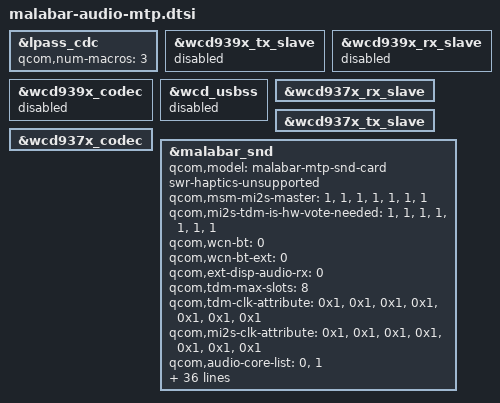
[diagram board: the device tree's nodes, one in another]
//
/* Copyright (c) Qualcomm Technologies, Inc. and/or its subsidiaries.
 * SPDX-License-Identifier: BSD-3-Clause-Clear
 */

#include "lpass-audio-cdc-1.0.dtsi"
#include "malabar-lpi.dtsi"
#include "lpass-audio-bt-swr.dtsi"
#include "lpass-cdc-gpio.dtsi"
#include "malabar-audio-lpass-reg.dtsi"
#include "wcd939x.dtsi"

&lpass_cdc {
	qcom,num-macros = <3>;
};

&wcd939x_tx_slave {
	status = "disabled";
};

&wcd939x_rx_slave {
	status = "disabled";
};

&wcd939x_codec {
	status = "disabled";
};

&wcd_usbss {
	status = "disabled";
};

&wcd937x_rx_slave {
	status = "okay";
};

&wcd937x_tx_slave {
	status = "okay";
};

&wcd937x_codec {
	status = "okay";
};

&malabar_snd {
	qcom,model = "malabar-mtp-snd-card";
	swr-haptics-unsupported;
	qcom,msm-mi2s-master = <1>, <1>, <1>, <1>, <1>, <1>, <1>;
	qcom,mi2s-tdm-is-hw-vote-needed = <1>, <1>, <1>, <1>, <1>, <1>, <1>;
	qcom,wcn-bt = <0>;
	qcom,wcn-bt-ext = <0>;
	qcom,ext-disp-audio-rx = <0>;
	qcom,tdm-max-slots = <8>;
	qcom,tdm-clk-attribute = <0x1>, <0x1>, <0x1>, <0x1>, <0x1>, <0x1>, <0x1>;
	qcom,mi2s-clk-attribute = <0x1>, <0x1>, <0x1>, <0x1>, <0x1>, <0x1>, <0x1>;
	qcom,audio-core-list = <0>, <1>;
	qcom,msm-mbhc-hs-mic-max-threshold-mv = <1670>;
	qcom,msm-mbhc-usbc-audio-supported = <0>;
	qcom,msm-mbhc-hphl-swh = <1>;
	qcom,msm-mbhc-gnd-swh = <1>;
	asoc-codec  = <&stub_codec>, <&lpass_cdc>,
			<&wcd937x_codec>, <&wsa881x_i2c_e>;
	asoc-codec-names = "msm-stub-codec.1", "lpass-cdc",
			"wcd937x_codec", "wsa-codec0";
	qcom,audio-routing =
			"AMIC2", "Analog Mic2",
			"AMIC2", "MIC BIAS2",
			"VA AMIC2", "Analog Mic2",
			"VA AMIC2", "VA MIC BIAS2",
			"TX DMIC0", "Digital Mic0",
			"TX DMIC0", "MIC BIAS1",
			"TX DMIC1", "Digital Mic1",
			"TX DMIC1", "MIC BIAS1",
			"TX DMIC2", "Digital Mic2",
			"TX DMIC2", "MIC BIAS3",
			"TX DMIC3", "Digital Mic3",
			"TX DMIC3", "MIC BIAS3",
			"IN1_HPHL", "HPHL_OUT",
			"IN2_HPHR", "HPHR_OUT",
			"IN3_AUX", "AUX_OUT",
			"RX_TX DEC0_INP", "TX DEC0 MUX",
			"RX_TX DEC1_INP", "TX DEC1 MUX",
			"RX_TX DEC2_INP", "TX DEC2 MUX",
			"RX_TX DEC3_INP", "TX DEC3 MUX",
			"TX SWR_INPUT", "WCD_TX_OUTPUT",
			"VA SWR_INPUT", "VA_SWR_CLK",
			"VA SWR_INPUT", "WCD_TX_OUTPUT",
			"VA_AIF1 CAP", "VA_SWR_CLK",
			"VA_AIF2 CAP", "VA_SWR_CLK",
			"VA_AIF3 CAP", "VA_SWR_CLK",
			"VA DMIC0", "Digital Mic0",
			"VA DMIC1", "Digital Mic1",
			"VA DMIC2", "Digital Mic2",
			"VA DMIC3", "Digital Mic3",
			"VA DMIC0", "VA MIC BIAS1",
			"VA DMIC1", "VA MIC BIAS1",
			"VA DMIC2", "VA MIC BIAS3",
			"VA DMIC3", "VA MIC BIAS3";
	qcom,wsa-max-devs = <0>;
	/*
	 * Add this property,
	 * To Enable swr haptics through OPCM port.
	 * This will include wsa2 dailinks.
	 */
	qcom,cdc-dmic01-gpios = <&cdc_dmic01_gpios>;
	qcom,cdc-dmic23-gpios = <&cdc_dmic23_gpios>;
	qcom,msm_audio_ssr_devs = <&audio_gpr>, <&lpi_tlmm>,
				  <&lpass_cdc>;

		/*
		 * ====================
		 * UPD backend - WSA
		 * ====================
		 *
		 * Mute/Unmute the interpolator
		 * ------------------------------
		 * Register:Â LPASS_WSA_CDC_RX0_RX_PATH_MIX_CTL - 0x6B00418
		 *
		 * Send control commands to the peripheral from the soundwire controller
		 * -----------------------------------------------------------------------
		 * Register: LPASS_WSA_SWR_MSTR_WSA_SWRM_CPUn_CMD_FIFO_WR_CMD - 0x6B14020
		 *
		 * Enable/Disable ear piece
		 * --------------------------
		 * Register:Â DIG_CTRL0_PA_FSM_EN - 0x3430
		 *
		 *
		 *	qcom,upd_backends_used = "wsa";
		 *	qcom,upd_lpass_reg_addr = <0x6B00418 0x6B14020>;
		 *	qcom,upd_ear_pa_reg_addr = <0x3430>;
		 *
		 *
		 * ====================
		 * UPD backend - WCD
		 * ====================
		 *
		 * Mute/Unmute the interpolator
		 * ------------------------------
		 * Register: LPASS_WCD_CDC_RX0_RX_PATH_MIX_CTL - 0x6AC0418
		 *
		 * Send control commands to the wcd from the soundwire controller
		 * ----------------------------------------------------------------
		 * Register: LPASS_WCD_SWR_MSTR_WSA_SWRM_CPUn_CMD_FIFO_WR_CMD - 0x7634020
		 *
		 * Enable/Disable ear piece
		 * --------------------------
		 * Register:Â DIG_CTRL0_PA_FSM_EN - 0x300A
		 *
		 */
//NEed this to update while review
	qcom,upd_backends_used = "wcd";
	qcom,upd_lpass_reg_addr = <0x6AC0418 0x7634020>;
	qcom,upd_ear_pa_reg_addr = <0x300A>;
};
